# cslr_srio register map
Vendor: Texas Instruments
Peripheral module from a debugger description file (folder tci6486).
Registers are 32-bit, access not given, reset 0x0 unless marked. A register's access mark holds for its fields unless they carry their own. Offsets are as the file gives them; lines under a group give offsets from that group; [hi:lo] are bit positions; {n}, {i} and the like mark numbered series; 'fields as' and 'values as' point back to an identical list; <NAME> marks a mode.

## SRIO (part 1 of 2) — Rapid input/output
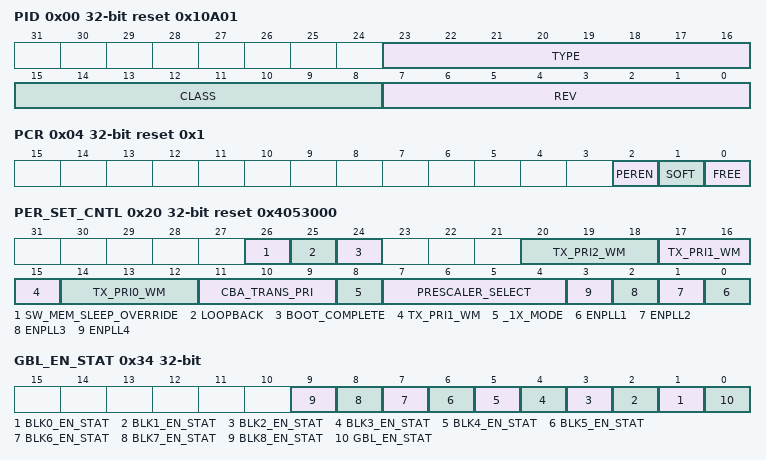
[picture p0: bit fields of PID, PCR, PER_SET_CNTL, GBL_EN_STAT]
0x00 PID reset 0x10A01 — Peripheral Identification Register
  [23:16] TYPE ro — Identifies the type of the peripheral
  [15:8] CLASS ro — Identifies the class of the peripheral
  [7:0] REV ro — Identifies the revision of the peripheral. This value should begin at 0x01 and be incremented each time the design is revised
0x04 PCR reset 0x1 — Peripheral Control register
  [2] PEREN rw — Peripheral Enable. Control the flow of data in the logical layer of the peripheral. As an initiator, it will prevent TX transaction generation and as a target, it will disable incoming requests. This should be the last enable bit to toggle when bringing the device out of reset to begin normal operation
  [1] SOFT rw — Emulation Control - SOFT bit
  [0] FREE rw — Emulation Control - FREE bit
0x20 PER_SET_CNTL reset 0x4053000 — Peripheral Settings Control register
  [26] SW_MEM_SLEEP_OVERRIDE rw — 0b0 - While in shutdown, memories are put in sleep mode 0b1 - While in shutdown, memories are not put in sleep mode
  [25] LOOPBACK rw — 0b: Normal operation 1b: Loop back. Trasmit data to receive on the same port.Packet data is looped back in the digital domain before the SerDes macros
  [24] BOOT_COMPLETE rw — Controls ability to write any register during initialization. It also includes read only registers during normal mode of operation, that have application defined reset value. 0 - write enabled 1 - write to read only registers disabled Usually the boot_complete is asserted once after reset to define power on configuration
  [20:18] TX_PRI2_WM rw — Transmit credit threshold. Sets the required number of logical layer TX buffers needed to send prority 2 packets across the UDI interface. This is valid for all ports in 1X mode only
  [17:15] TX_PRI1_WM rw — Transmit credit threshold. Sets the required number of logical layer TX buffers needed to send prority 1 packets across the UDI interface. This is valid for all ports in 1X mode only
  [14:12] TX_PRI0_WM rw — Transmit credit threshold. Sets the required number of logical layer TX buffers needed to send prority 0 packets across the UDI interface. This is valid for all ports in 1X mode only
  [11:9] CBA_TRANS_PRI rw — VBUS transaction priority
  [8] _1X_MODE rw — This register bit determines the UDI buffering setup(Prority versus Port).
  [7:4] PRESCALER_SELECT rw — Internal frequency prescaler, used to drive the request to response timers
  [n-1] ENPLL{n} rw (n=1..4) — Drives SerDes Macro {n} PLL Enable signal
0x30 GBL_EN — Peripheral Global Enable register
  [0] EN rw — Controls reset to all clock domains within the peripheral
0x34 GBL_EN_STAT (reset mask 0xFFFFFC00) — Peripheral Global Enable Status
  [n+1] BLK{n}_EN_STAT ro (n=0..8) — Indicates state of BLK{n}_EN reset signal
  [0] GBL_EN_STAT ro — Indicates state of GBL_EN reset signal
0x38 BLK_ENABLE_{i}_BLK_EN (reset mask 0xFFFFFFFE) (i=0..8) — Block Enable
  [0] EN rw — Controls reset to Logical block n (0 to 8)
0x3C BLK_ENABLE_{i}_BLK_EN_STAT (reset mask 0xFFFFFFFE) (i=0..8) — Block Enable Status
  [0] EN_STAT ro — Indicates state of BLKn_EN reset signal
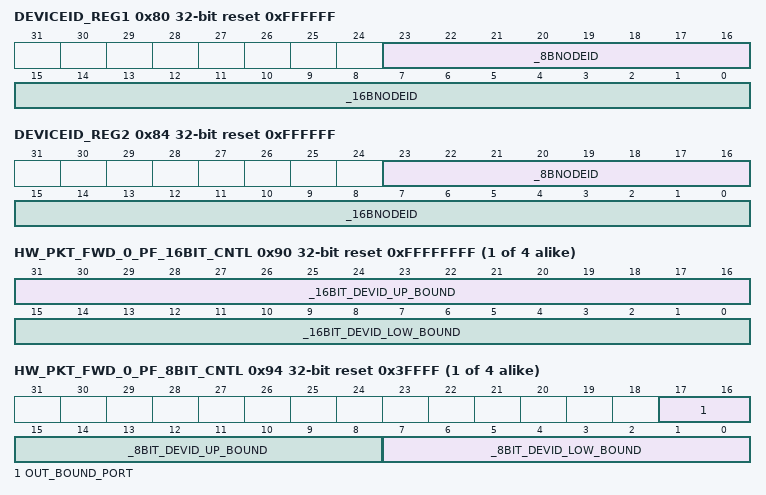
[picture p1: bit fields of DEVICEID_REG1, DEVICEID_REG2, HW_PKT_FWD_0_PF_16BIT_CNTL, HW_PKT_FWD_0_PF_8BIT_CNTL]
0x80 DEVICEID_REG1 reset 0xFFFFFF — RapidIO DEVICEID1 Register
  [23:16] _8BNODEID rw — This value is equal to the value of the RapidIO Base Device ID CSR. The CPU must read the CSR value and set this register, so that out-going packets contain the correct SOURCEID value
  [15:0] _16BNODEID rw — This value is equal to the value of the RapidIO Base Device ID CSR. The CPU must read the CSR value and set this register, so that out-going packets contain the correct SOURCEID value
0x84 DEVICEID_REG2 reset 0xFFFFFF — RapidIO DEVICEID2 Register
  [23:16] _8BNODEID rw — This is a secondary supported DeviceID checked against an in-coming packet's DestID field. Typically used for Multi-cast support
  [15:0] _16BNODEID rw — This is a secondary supported DeviceID checked against an in-coming packet's DestID field. Typically used for Multi-cast support
0x90 HW_PKT_FWD_{i}_PF_16BIT_CNTL rw reset 0xFFFFFFFF (i=0..3) — Packet Forwarding register for 16b DeviceIDs
  [31:16] _16BIT_DEVID_UP_BOUND — Upper 16b DeviceID boundary. DestID above this range cannot use the table entry
  [15:0] _16BIT_DEVID_LOW_BOUND — Lower 16b DeviceID boundary. DestID lower than this number cannot use the table entry
0x94 HW_PKT_FWD_{i}_PF_8BIT_CNTL reset 0x3FFFF (i=0..3) — Packet Forwarding register for 8b DeviceIDs
  [17:16] OUT_BOUND_PORT rw — Output port number for packet's whose DestID falls within the 8b or 16b range for this table entry
  [15:8] _8BIT_DEVID_UP_BOUND rw — Upper 8b DeviceID boundary. DestID above this range cannot use the table entry
  [7:0] _8BIT_DEVID_LOW_BOUND rw — Lower 8b DeviceID boundary. DestID lower than this number cannot use the table entry
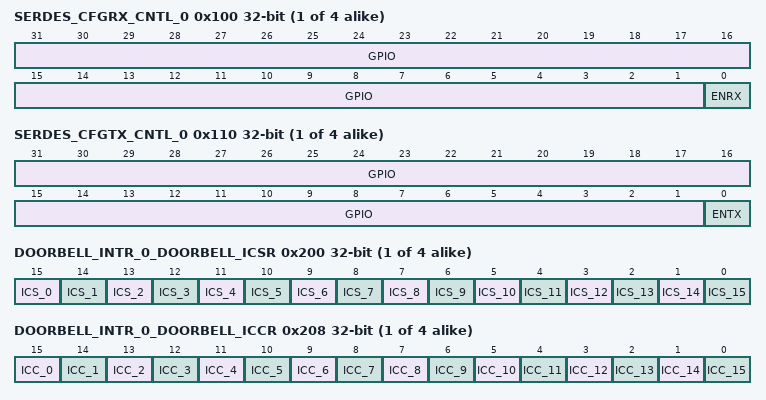
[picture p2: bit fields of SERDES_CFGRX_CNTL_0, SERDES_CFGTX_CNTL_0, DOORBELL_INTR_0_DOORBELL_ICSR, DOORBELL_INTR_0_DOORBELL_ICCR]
{0x100+4i} SERDES_CFGRX_CNTL_{i} rw (i=0..3) — SerDes RX Channels CFG register
  [31:1] GPIO — General Purpose I/O bits can be used to control any SerDes control functions. Mapping of GPIO bits is device specific based on the SerDes macro that is implemented
  [0] ENRX — Receive enable. This bit is logically "AND" together with the physical layer state machine to control the SerDes
{0x110+4i} SERDES_CFGTX_CNTL_{i} rw (i=0..3) — SerDes TX Channels CFG register
  [31:1] GPIO — General Purpose I/O bits can be used to control any SerDes control functions. Mapping of GPIO bits is device specific based on the SerDes macro that is implemented
  [0] ENTX — Trasmit enable. This bit is logically "AND" together with the physical layer state machine to control the SerDes
{0x120+4i} SERDES_CFG_CNTL_{i} rw (i=0..3) — SerDes Macros CFG register
  [31:0] GPIO — General Purpose I/O bits can be used to control any SerDes control functions. Mapping of GPIO bits is device specific based on the SerDes macro that is implemented
{0x200+0x10*i} DOORBELL_INTR_{i}_DOORBELL_ICSR (i=0..3) — DOORBELL Interrupt Status register
  [15-n] ICS_{n} ro (n=0..15) — Doorbell n (0 to 3) interrupt condition status bits
{0x208+0x10*i} DOORBELL_INTR_{i}_DOORBELL_ICCR (i=0..3) — DOORBELL Interrupt Clear register
  [15-n] ICC_{n} wo (n=0..15) — Doorbell n (0 to 3) interrupt clear bits
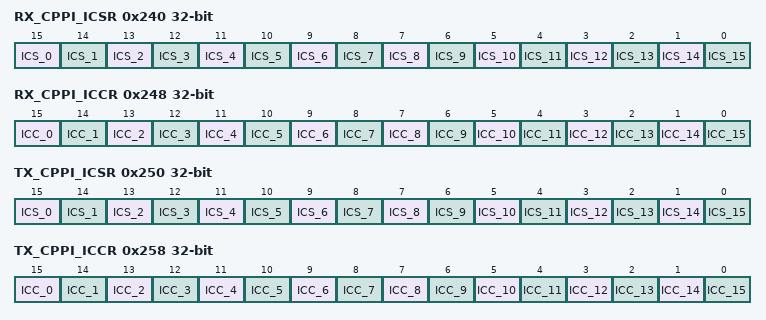
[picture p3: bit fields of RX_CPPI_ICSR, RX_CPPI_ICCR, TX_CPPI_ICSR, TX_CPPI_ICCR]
0x240 RX_CPPI_ICSR — RX CPPI Interrupt Status register
  [15-n] ICS_{n} ro (n=0..15) — RX CPPI Interrupt, Buffer descriptor Queue 0 to 15
0x248 RX_CPPI_ICCR — RX CPPI Interrupt Clear register
  [15-n] ICC_{n} wo (n=0..15) — RX CPPI Interrupt clear, Buffer descriptor Queue 0 to 15
0x250 TX_CPPI_ICSR — TX CPPI Interrupt Status register
  [15-n] ICS_{n} ro (n=0..15) — TX CPPI Interrupt, Buffer descriptor Queue 0 to 15
0x258 TX_CPPI_ICCR — TX CPPI Interrupt Clear register
  [15-n] ICC_{n} wo (n=0..15) — TX CPPI Interrupt clear, Buffer descriptor Queue 0 to 15
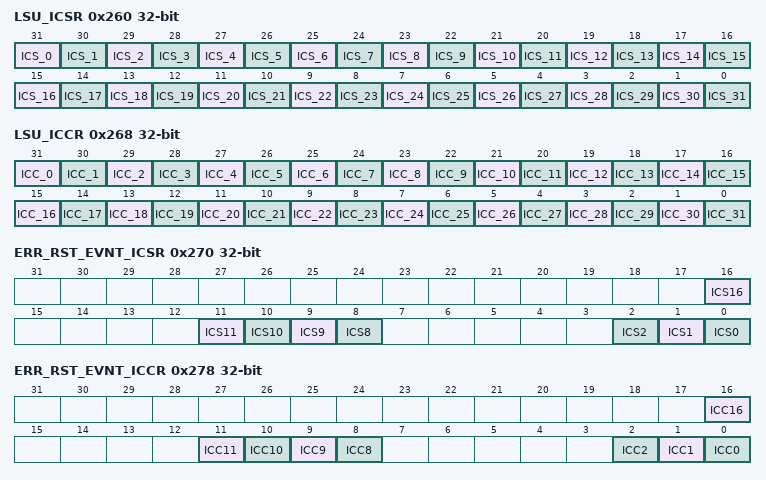
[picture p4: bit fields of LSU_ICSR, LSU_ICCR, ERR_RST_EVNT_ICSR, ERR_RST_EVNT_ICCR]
0x260 LSU_ICSR ro — LSU Status Interrupt register
  [31-n] ICS_{n} (n=0..31) — Load/Store module interrupt condition status bits
0x268 LSU_ICCR wo — LSU Clear Interrupt register
  [31-n] ICC_{n} (n=0..31) — Load/Store module interrupt clear bits
0x270 ERR_RST_EVNT_ICSR — Error, Reset, and Special Event Status Interrupt register
  [16] ICS16 ro — Device Reset Interrupt from any port
  [n] ICS{n} ro (n=8..11) — Port{n-8} Error
  [2] ICS2 ro — Logical Layer Error Management Event Capture
  [1] ICS1 ro — Port-write-In request received on any port
  [0] ICS0 ro — Multi-cast event control symbol interrupt received on any port
0x278 ERR_RST_EVNT_ICCR — Error, Reset, and Special Event Clear Interrupt register
  [16] ICC16 wo — Device Reset Interrupt from any port
  [n] ICC{n} wo (n=8..11) — Port{n-8} Error
  [2] ICC2 wo — Logical Layer Error Management Event Capture
  [1] ICC1 wo — Port-write-In request received on any port
  [0] ICC0 wo — Multi-cast event control symbol interrupt received on any port
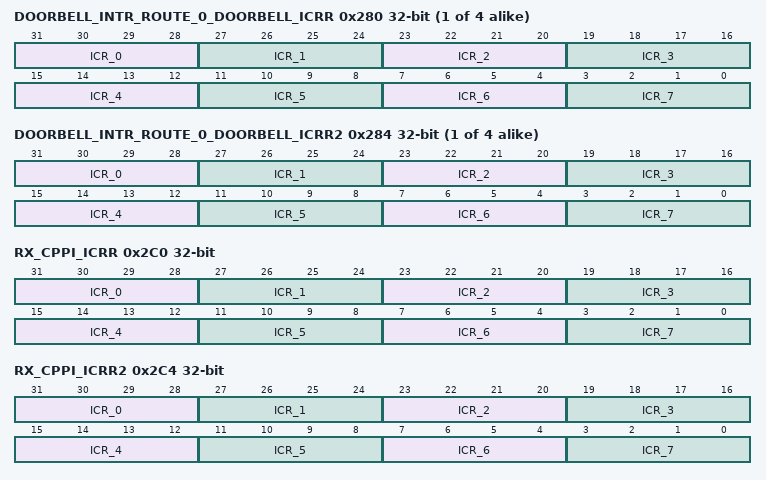
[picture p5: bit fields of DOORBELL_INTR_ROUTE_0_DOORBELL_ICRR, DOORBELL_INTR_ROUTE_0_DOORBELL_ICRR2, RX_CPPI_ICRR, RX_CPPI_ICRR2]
{0x280+0x10*i} DOORBELL_INTR_ROUTE_{i}_DOORBELL_ICRR rw (i=0..3) — DOORBELL Interrupt Condition Routing register (0 to 7)
  [31-4n:28-4n] ICR_{n} (n=0..7) — Doorbell n (0 to 3) CPU servicing interrupt condition routing bits
{0x284+0x10*i} DOORBELL_INTR_ROUTE_{i}_DOORBELL_ICRR2 rw (i=0..3) — DOORBELL Interrupt Condition Routing register (8 to 15)
  fields as DOORBELL_INTR_ROUTE_0_DOORBELL_ICRR
0x2C0 RX_CPPI_ICRR rw — RX CPPI Interrupt Condition Routing register (0 to 7)
  [31-4n:28-4n] ICR_{n} (n=0..7) — RX CPPI Interrupt condition routing bits
0x2C4 RX_CPPI_ICRR2 rw — RX CPPI Interrupt Condition Routing register (8 to 15)
  fields as RX_CPPI_ICRR
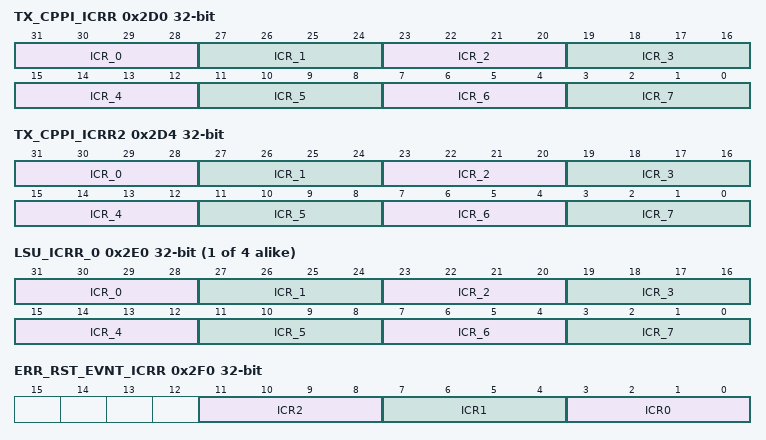
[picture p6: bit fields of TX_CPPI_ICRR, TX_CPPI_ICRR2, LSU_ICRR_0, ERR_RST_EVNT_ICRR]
0x2D0 TX_CPPI_ICRR rw — TX CPPI Interrupt Condition Routing register (0 to 7)
  [31-4n:28-4n] ICR_{n} (n=0..7) — TX CPPI Interrupt condition routing bits
0x2D4 TX_CPPI_ICRR2 rw — TX CPPI Interrupt Condition Routing register (8 to 15)
  fields as TX_CPPI_ICRR
{0x2E0+4i} LSU_ICRR_{i} rw (i=0..3) — LSU Module Interrupt Condition Routing register
  [31-4n:28-4n] ICR_{n} (n=0..7) — Load/Store module interrupt condtion routing bits
0x2F0 ERR_RST_EVNT_ICRR — Err/Reset/special event Interrupt Condition Routing register
  [11:8] ICR2 rw — Logical Layer Error Management Event Capture routing
  [7:4] ICR1 rw — Routing of Port-write-In request received on any port
  [3:0] ICR0 rw — Routing of Multi-cast event control symbol interrupt received on any port
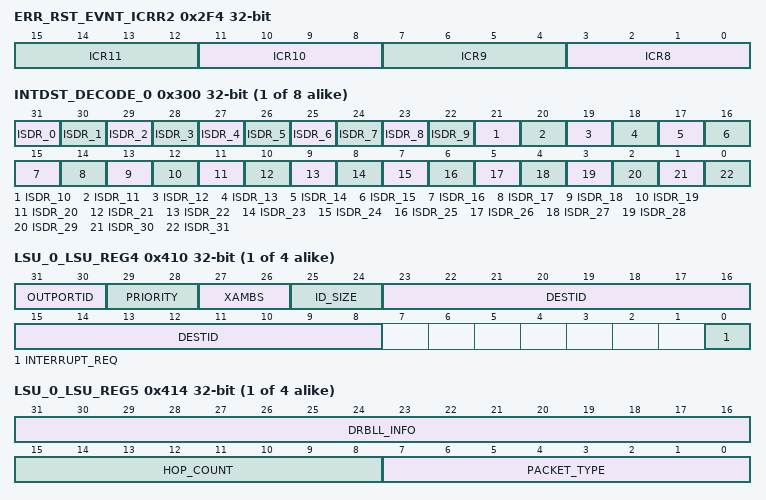
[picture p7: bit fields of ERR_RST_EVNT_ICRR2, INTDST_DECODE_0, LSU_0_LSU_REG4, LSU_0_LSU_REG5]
0x2F4 ERR_RST_EVNT_ICRR2 — Err/Reset/special event Interrupt Condition Routing register
  [4n-29:4n-32] ICR{n} rw (n=8..11) — Port{n-8} Error routing
0x2F8 ERR_RST_EVNT_ICRR3 — Err/Reset/special event Interrupt Condition Routing register
  [3:0] ICR16 rw — Routing of Device Reset Interrupt from any port
{0x300+4i} INTDST_DECODE_{i} ro (i=0..7) — INTDST Interrupt Status Decode registers
  [31-n] ISDR_{n} (n=0..31) — Interrupt sources that select a particular physical interrupt destination, are mapped to specific bits in the decode register. The interrupt sources are mapped to an interrupt decode register, only if the ICRR routes the interrupt source to the corresponding physical interrupt. The status decode bit is a logical "OR" of multiple interrupt sources that are mapped to the same bit.
{0x320+4i} INTDST_RATE_CNTL_{i} rw (i=0..7) — INTDST Interrupt Rate Control registers
  [31:0] COUNT_DOWN_VALUE — The rate at which an interrupt can be generated is controllable for each physical interrupt destination. Rate control is implemented with a programmable down-counter. The counter re-loads and immediately starts down-counting each time the CPU writes these registers. Once the rate control counter register is written, and the counter value reaches zero (note the CPU may write zero immediately for a zero count), the interrupt pulse generation logic is allowed to fire a single pulse if any bits in the corresponding ICSR register bits are set (or become set after the zero count is reached). .
0x400 LSU_{i}_LSU_REG0 rw (i=0..3) — LSU Control register0
  [31:0] ADDRESS_MSB — 32 bit Ext address fields
0x404 LSU_{i}_LSU_REG1 rw (i=0..3) — LSU Control register1
  [31:0] ADDRESS_LSB_CONFIG_OFFSET — 1) 32b Address - Packet Types 2,5, and 6 (Will be used in conjunction with BYTE_COUNT to create 64b aligned RapidIO packet header address) 2) 24b Config_offset Field - Maintenance Packets Type 8 (Will be used in conjunction with BYTE_COUNT to create 64b aligned RapidIO packet header Config_offset); The 2 lsb of this field must be zero since the smallest configuration access is 4B.
0x408 LSU_{i}_LSU_REG2 rw (i=0..3) — LSU Control register2
  [31:0] DSP_ADDRESS — 32b DSP byte address
0x40C LSU_{i}_LSU_REG3 (i=0..3) — LSU Control register3
  [11:0] BYTE_COUNT rw — Number of data bytes to Read/Write - up to 4KB. (Used in conjunction with RapidIO address to create WRSIZE/RDSIZE and WDPTR in RapidIO packet header).
0x410 LSU_{i}_LSU_REG4 (i=0..3) — LSU Control register4
  [31:30] OUTPORTID rw — Not applicable for Rapid IO header. Indicates the output port number for the packet to be transmitted from. Specified by the CPU along with NodeID.
  [29:28] PRIORITY rw — RapidIO prio field specifying packet priority. Request packets should not be sent at a priority level of 3 in order to avoid system deadlock. It is the responsibility of the software to assign the appropriate out-going priority.
  [27:26] XAMBS rw — RapidIO xambs field specifying extended address MSB
  [25:24] ID_SIZE rw — RapidIO tt field specifying 8 or 16bit DeviceIDs
  [23:8] DESTID rw — RapidIO destinationID field specifying target device
  [0] INTERRUPT_REQ rw — CPU controlled request bit used for interrupt generation. Typically used in conjunction with non-posted commands to alert the CPU when the requested data/status is present. 0b0 - An interrupt is not requested upon completion of command 0b1- An interrupt is requested upon completion of command
0x414 LSU_{i}_LSU_REG5 rw (i=0..3) — LSU Control register5
  [31:16] DRBLL_INFO — RapidIO doorbell info field for type 10 packets
  [15:8] HOP_COUNT — RapidIO hop_count field specified for Type 8 Maintenance packets
  [7:0] PACKET_TYPE — 4 msb = 4b ftype field for all packets and 4 lsb = 4b trans field for Packet types 2,5,8
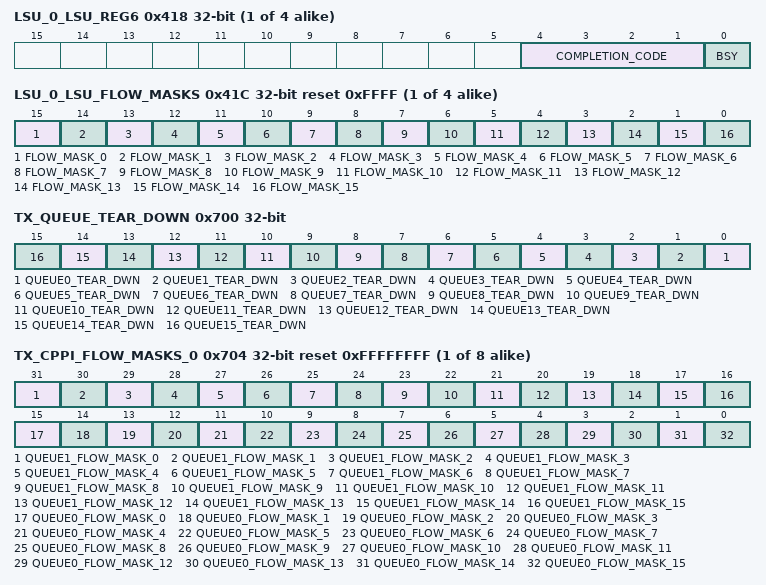
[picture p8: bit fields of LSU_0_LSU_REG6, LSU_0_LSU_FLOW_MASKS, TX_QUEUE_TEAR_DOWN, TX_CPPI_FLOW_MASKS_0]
0x418 LSU_{i}_LSU_REG6 (i=0..3) — LSU Control register6
  [4:1] COMPLETION_CODE ro — Indicates the status of the pending command 0b000 - Transaction complete, No Errors (Posted/Non-posted) 0b001 - Transaction Timeout occurred on Non-posted transaction 0b010 - Transaction complete, Packet not sent due to flow control blockade (Xoff) 0b011 - Transaction complete, Non-posted response packet (type 8 and 13) contained ERROR status, or response payload length was in error 0b100 - Transaction complete, Packet not sent due to unsupported transaction type or invalid programming encoding for one or more LSU register fields 0b101 - DMA data transfer error 0b110 - "Retry" DOORBELL response received, or Atomic Test-and-swap was not allowed (semaphore in use) 0b111 - Transaction complete, Packet not sent due to unavailable outbound credit at given priority
  [0] BSY ro — Indicates status of the command registers 0b0 - Command registers are available(writable) for next set of transfer descriptors 0b1 - Command registers are busy with current transfer
0x41C LSU_{i}_LSU_FLOW_MASKS reset 0xFFFF (i=0..3) — Core n LSU Congestion Control Flow Mask
  [15-n] FLOW_MASK_{n} rw (n=0..15) — LSU flow masks
{0x500+4i} QUEUE_TXDMA_HDP_{i} rw (i=0..15) — Queue TX DMA Head Descriptor Pointer
  [31:0] TX_HDP — This field is the host memory address for the first buffer descriptor in the transmit queue. This field is written by the host to initiate queue transmit operations and is zeroed by the port when all packets in the queue have been transmitted. An error condition results if the host writes this field when the current field value is nonzero. The address must be 32-bit word aligned
{0x580+4i} QUEUE_TXDMA_CP_{i} rw (i=0..15) — Queue TX DMA Completion Pointer
  [31:0] TX_CP — This field is the host memory address for the transmit queue completion pointer. This register is written by the host with the buffer descriptor address for the last buffer processed by the host during interrupt processing. The port uses the value written to determine if the interrupt should be deasserted.
{0x600+4i} QUEUE_RXDMA_HDP_{i} rw (i=0..15) — Queue RX DMA Head Descriptor Pointer
  [31:0] RX_HDP — Rx Queue Head Descriptor Pointer: This field is the host memory address for the first buffer descriptor in the channel receive queue. This field is written by the host to initiate queue receive operations and is zeroed by the port when all free buffers have been used. An error condition results if the host writes this field when the current field value is nonzero. The address must be 32-bit word aligned.
{0x680+4i} QUEUE_RXDMA_CP_{i} rw (i=0..15) — Queue RX DMA Completion Pointer
  [31:0] RX_CP — Rx Queue Completion Pointer: This field is the host memory address for the receive queue completion pointer. This register is written by the host with the buffer descriptor address for the last buffer processed by the host during interrupt processing. The port uses the value written to determine if the interrupt should be deasserted
0x700 TX_QUEUE_TEAR_DOWN
  [n] QUEUE{n}_TEAR_DWN wo (n=0..15) — Write = 1, tear down of Queue {n}
{0x704+4i} TX_CPPI_FLOW_MASKS_{i} rw reset 0xFFFFFFFF (i=0..7) — TX CPPI Supported Flow Mask
  [31-n] QUEUE1_FLOW_MASK_{n} (n=0..15) — 0b0 - TX source doesn't support Flow n (0 to 15) from table entry for QUEUE1 0b1 - TX source does support Flow n ( 0 to 15) from table entry for QUEUE1
  [15-n] QUEUE0_FLOW_MASK_{n} (n=0..15) — 0b0 - TX source doesn't support Flow n (0 to 15) from table entry for QUEUE0 0b1 - TX source does support Flow n ( 0 to 15) from table entry for QUEUE0
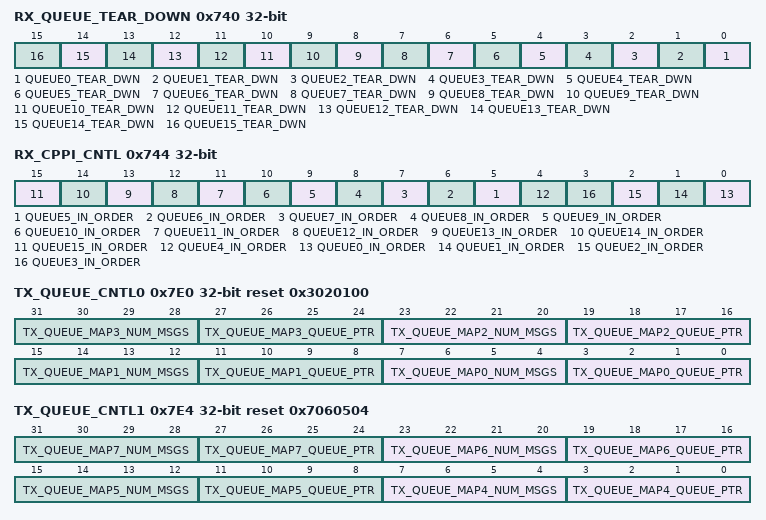
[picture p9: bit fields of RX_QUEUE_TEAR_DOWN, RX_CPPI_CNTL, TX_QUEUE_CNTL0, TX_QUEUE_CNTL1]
0x740 RX_QUEUE_TEAR_DOWN
  fields as TX_QUEUE_TEAR_DOWN
0x744 RX_CPPI_CNTL — RX CPPI Control register
  [n] QUEUE{n}_IN_ORDER rw (n=5..15) — 0b0 - allows out-of-order message 0b1- only allows in-order messages. Used for applications with dedicated source-destination flows
  [4] QUEUE4_IN_ORDER rw — 0b0 - allows out-of-order message 0b1- only allows in-order messages Used for applications with dedicated source-destination flows
  [n] QUEUE{n}_IN_ORDER rw (n=0..3) — 0b0 - allows out-of-order message 0b1- only allows in-order messages. Used for applications with dedicated source-destination flows
0x7E0 TX_QUEUE_CNTL0 rw reset 0x3020100 — TX CPPI Weighted Round Robin Control
  [8n+7:8n+4] TX_QUEUE_MAP{n}_NUM_MSGS (n=0..3) — Number of contiguous messages (descriptors) to process before moving to TX_Queue_Map{n+1}
  [8n+3:8n] TX_QUEUE_MAP{n}_QUEUE_PTR (n=0..3) — Pointer to a Queue, programmable to any of the 16 TX queues
0x7E4 TX_QUEUE_CNTL1 rw reset 0x7060504 — TX CPPI Weighted Round Robin Control
  [8n-25:8n-28] TX_QUEUE_MAP{n}_NUM_MSGS (n=4..7) — Number of contiguous messages (descriptors) to process before moving to TX_Queue_Map{n+1}
  [8n-29:8n-32] TX_QUEUE_MAP{n}_QUEUE_PTR (n=4..7) — Pointer to a Queue, programmable to any of the 16 TX queues
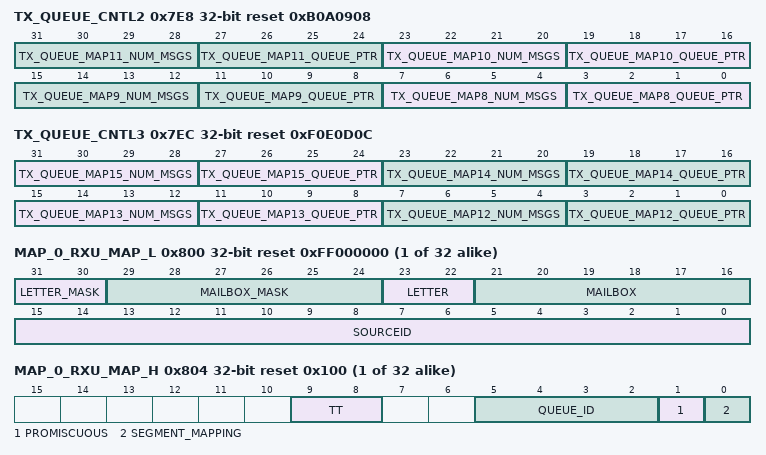
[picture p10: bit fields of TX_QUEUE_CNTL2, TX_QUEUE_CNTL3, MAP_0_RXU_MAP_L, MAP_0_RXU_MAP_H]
0x7E8 TX_QUEUE_CNTL2 rw reset 0xB0A0908 — TX CPPI Weighted Round Robin Control
  [8n-57:8n-60] TX_QUEUE_MAP{n}_NUM_MSGS (n=8..11) — Number of contiguous messages (descriptors) to process before moving to TX_Queue_Map{n+1}
  [8n-61:8n-64] TX_QUEUE_MAP{n}_QUEUE_PTR (n=8..11) — Pointer to a Queue, programmable to any of the 16 TX queues
0x7EC TX_QUEUE_CNTL3 rw reset 0xF0E0D0C — TX CPPI Weighted Round Robin Control
  [31:28] TX_QUEUE_MAP15_NUM_MSGS — Number of contiguous messages (descriptors) to process before moving to TX_Queue_Map0
  [8n-93:8n-96] TX_QUEUE_MAP{n}_QUEUE_PTR (n=12..15) — Pointer to a Queue, programmable to any of the 16 TX queues
  [23:20] TX_QUEUE_MAP14_NUM_MSGS — Number of contiguous messages (descriptors) to process before moving to TX_Queue_Map15
  [15:12] TX_QUEUE_MAP13_NUM_MSGS — Number of contiguous messages (descriptors) to process before moving to TX_Queue_Map14
  [7:4] TX_QUEUE_MAP12_NUM_MSGS — Number of contiguous messages (descriptors) to process before moving to TX_Queue_Map13
0x800 MAP_{i}_RXU_MAP_L rw reset 0xFF000000 (i=0..31) — MailBox-to-queue mapping register
  [31:30] LETTER_MASK — Allowed letter mask for this mapping register
  [29:24] MAILBOX_MASK — Allowed mail box mask for this mapping register
  [23:22] LETTER — Allowed letter for this mapping register
  [21:16] MAILBOX — Allowed mail box for this mapping register
  [15:0] SOURCEID — The SOURCEID field is used to indicate which external device has access to the mapping entry and corresponding queue. A compare is performed between the sourceID of the incoming message packet and each relevant mailbox/letter table mapping entry SOURCEID field. A mis-compare results in an ERROR response back to the sender and the transaction is logged in the Logical Layer Error Management capture registers
0x804 MAP_{i}_RXU_MAP_H reset 0x100 (i=0..31) — MailBox-to-queue mapping register
  [9:8] TT rw — Transport type 0b0: matches the 8 LSB of the source ID 0b1: matches the full 16 bits of the source ID
  [5:2] QUEUE_ID rw — Corresponding queue 0 to queue 15
  [1] PROMISCUOUS rw — Promiscuous =1, full access to the queue for any source ID
  [0] SEGMENT_MAPPING rw — 0b0 - single segment (all six bits of mailbox valid ) 0b1 - Multi segment(only 2 LSBs of Mailbox valid )
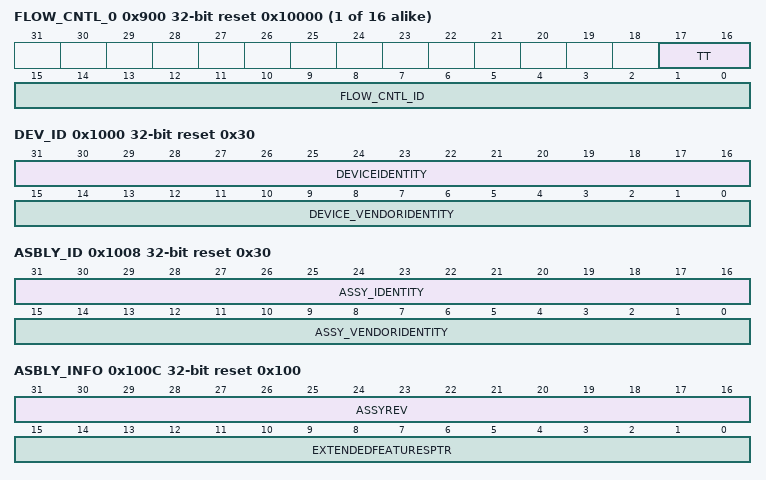
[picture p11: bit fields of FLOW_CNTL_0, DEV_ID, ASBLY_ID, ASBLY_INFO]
{0x900+4i} FLOW_CNTL_{i} reset 0x10000 (i=0..15) — Flow Control Table Entry Registers
  [17:16] TT rw — Selects Flow_Cntl_ID length. 0b00 - 8b Ids 0b01 - 16b Ids 0b10 - 0b11 - reserved
  [15:0] FLOW_CNTL_ID rw — DestID of Flow n
0x1000 DEV_ID ro reset 0x30 — Device Identity CAR
  [31:16] DEVICEIDENTITY — Identifies the type of device. Vendor specific
  [15:0] DEVICE_VENDORIDENTITY — Device Vendor ID assigned by RapidIO TA
0x1004 DEV_INFO ro — Device Information CAR
  [31:0] DEVICEREV — Vendor supply device revision
0x1008 ASBLY_ID ro reset 0x30 — Assembly Identity CAR
  [31:16] ASSY_IDENTITY — Assembly Identifier. Vendor Specific
  [15:0] ASSY_VENDORIDENTITY — Assembly Vendor Identifier assigned by RapidIO TA.
0x100C ASBLY_INFO ro reset 0x100 — Assembly Information CAR
  [31:16] ASSYREV — Assembly revision level
  [15:0] EXTENDEDFEATURESPTR — Pointer to first entry in extended features list
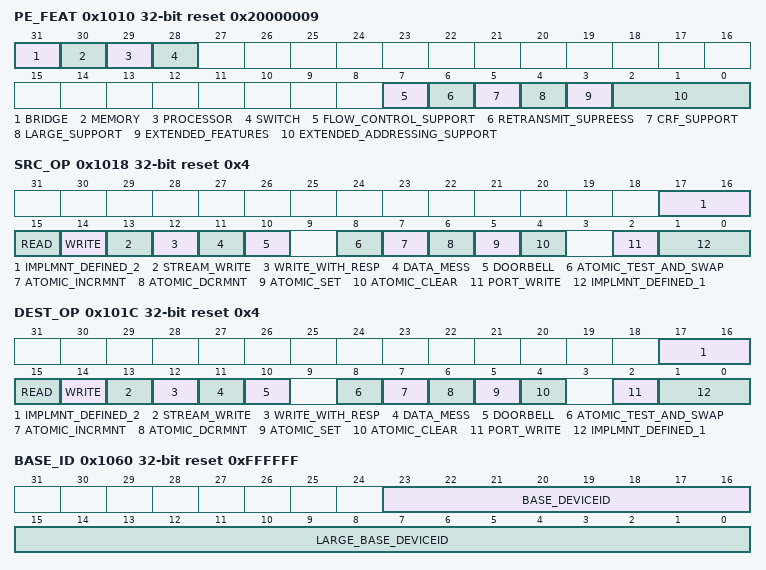
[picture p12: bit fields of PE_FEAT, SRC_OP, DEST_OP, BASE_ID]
0x1010 PE_FEAT reset 0x20000009 — Processing Element Features CAR
  [31] BRIDGE ro — PE can bridge to another interface. Examples are PCI, proprietary processor buses, DRAM, etc.
  [30] MEMORY ro — PE has physically addressable local address space and can be accessed as an end point through non-maintenance (i.e. non-coherent read and write) operations. This local address space may be limited to local configuration registers, or could be on-chip SRAM, etc.
  [29] PROCESSOR ro — PE physically contains a local processor or similar device that executes code. A device that bridges to an interface that connects to a processor does not count
  [28] SWITCH ro — PE can bridge to another external RapidIO interface - an internal port to a local end point does not count as a switch port. For example, a device with two RapidIO ports and a local end point is a two port switch, not a three port switch, regardless of the internal architecture
  [7] FLOW_CONTROL_SUPPORT ro — PE supports congestion flow control mechanism 0b1 - PE supports flow control
  [6] RETRANSMIT_SUPREESS ro — PE supports suppression of error recovery on packet CRC errors.0b1 - PE supports suppression
  [5] CRF_SUPPORT ro — This bit indicates PE support for the Critical Request Flow (CRF) Function 0b1 - PE supports CRF Function
  [4] LARGE_SUPPORT ro — 0b0 - PE does not support common transport large systems 0b1 - PE supports common transport large systems
  [3] EXTENDED_FEATURES ro — PE has extended features list; the extended features pointer is valid
  [2:0] EXTENDED_ADDRESSING_SUPPORT ro — Indicates the number address bits supported by the PE both as a source and target of an operation. All PEs shall at minimum support 34 bit addresses. 0b111 - PE supports 66, 50 and 34 bit addresses 0b101 - PE supports 66 and 34 bit addresses 0b011 - PE supports 50 and 34 bit addresses 0b001 - PE supports 34 bit addresses All other encodings reserved
0x1018 SRC_OP reset 0x4 — Source Operations CAR
  [17:16] IMPLMNT_DEFINED_2 ro — Defined by the device implementation
  [15] READ ro — PE can support a read operation
  [14] WRITE ro — PE can support a write operation
  [13] STREAM_WRITE ro — PE can support a streaming-write operation
  [12] WRITE_WITH_RESP ro — PE can support a write-with-response operation
  [11] DATA_MESS ro — PE can support a data message operation
  [10] DOORBELL ro — PE can support a doorbell operation
  [8] ATOMIC_TEST_AND_SWAP ro — PE can support an atomic test-and-swap operation
  [7] ATOMIC_INCRMNT ro — PE can support an atomic increment operation
  [6] ATOMIC_DCRMNT ro — PE can support an atomic decrement operation
  [5] ATOMIC_SET ro — PE can support an atomic set operation
  [4] ATOMIC_CLEAR ro — PE can support an atomic clear operation
  [2] PORT_WRITE ro — PE can support a port-write generation
  [1:0] IMPLMNT_DEFINED_1 ro — Defined by the device implementation
0x101C DEST_OP reset 0x4 — Destination Operations CAR
  fields as SRC_OP
0x104C PE_LL_CTL reset 0x1 — Processing Element Logical Layer Control CSR
  [2:0] EXTENDED_ADDRESSING_CONTROL rw — Controls the number of address bits generated by the PE as a source and processed by the PE as the target of an operation. 0b100 - PE supports 66 bit addresses 0b010 - PE supports 50 bit addresses 0b001 - PE supports 34 bit addresses (default) All other encodings reserved
0x1058 LCL_CFG_HBAR — Local Configuration Space Base Address 0 CSR
  [30:0] LCSBA ro — For bits 30 to 15 Reserved for 34b addresses Reserved for 50b addresses Bits 66-51 of a 66b address For bits 14 to 0 Reserved for 34b addresses Bits 50-36 of a 50b address Bits 50-36 of a 66b address
0x105C LCL_CFG_BAR ro — Local Configuration Space Base Address 1 CSR
  [31:0] LCSBA — For bit 31 Reserved for 34b addresses Bit 35 of a 50b address Bit 35 of a 66b address For bits 30 to 0 Bits 34-3 of a 34b address, Bits 35-3 of a 50b address Bits 35-3 of a 66b address
0x1060 BASE_ID reset 0xFFFFFF — Base Device ID CSR
  [23:16] BASE_DEVICEID rw — This is the base ID of the device in small common transport system (End points only)
  [15:0] LARGE_BASE_DEVICEID rw — This is the base ID of the device in a large common transport system (Only valid for end points, and if bit 4 of the PEFTR register is set)
0x1068 HOST_BASE_ID_LOCK reset 0xFFFF — Host Base Device ID Lock CSR
  [15:0] HOST_BASE_DEVICEID rw — This is the base ID for the Host PE that is initializing this PE
0x106C COMP_TAG rw — Component Tag CSR
  [31:0] COMPONENT_TAG — Software defined component Tag for PE. Useful for devices without device IDs
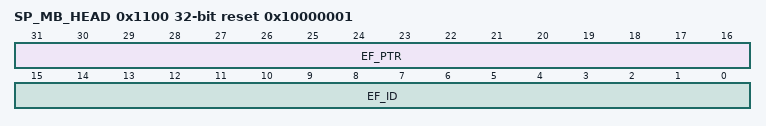
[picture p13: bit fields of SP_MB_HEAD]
0x1100 SP_MB_HEAD ro reset 0x10000001 — 1x/4x LP-Serial Port Maintenance Block Header
  [31:16] EF_PTR — Hard wired pointer to the next block in the data structure.
  [15:0] EF_ID — Hard-wired extended features ID, 0x0001 - general endpoint device 0x0002 - general endpoint device with software assisted error recovery option. 0x0003 - Switch
0x1120 SP_LT_CTL reset 0xFFFFFF00 — Port Link Time-Out Control CSR
  [31:8] TIMEOUT_VALUE rw — Timeout value for all ports on the device. This timeout is for link events such as sending a packet to receiving the corresponding ACK. Max value represents 3-6 seconds.Timeout duration = 205nS * Timeout Value; Where, Timeout value is the decimal representation of this register value. FFFFFFh = 3.4 seconds 0FFFFFh = 215 ms 00FFFFh = 13.4 ms 000FFFh = 839.5 us 0000FFh = 52.3 us 00000Fh = 3.1 us 000001h = 205 ns for simulation only 000000h = Timer disabled
0x1124 SP_RT_CTL reset 0xFFFFFF00 — Port Response Time-Out Control CSR
  [31:8] TIMEOUT_VALUE rw — Timeout value for all ports on the device. This timeout is for sending a packet to receiving the corresponding response packet. Max value represents 3-6 seconds. The timeout duration can be expressed as:Timeout = 15 * ((Prescale value + 1) * DMA clock period * Timeout Value) Where, Prescale value is set in 0x0020 PSCR and the Timeout value is the decimal representation of this register value.
